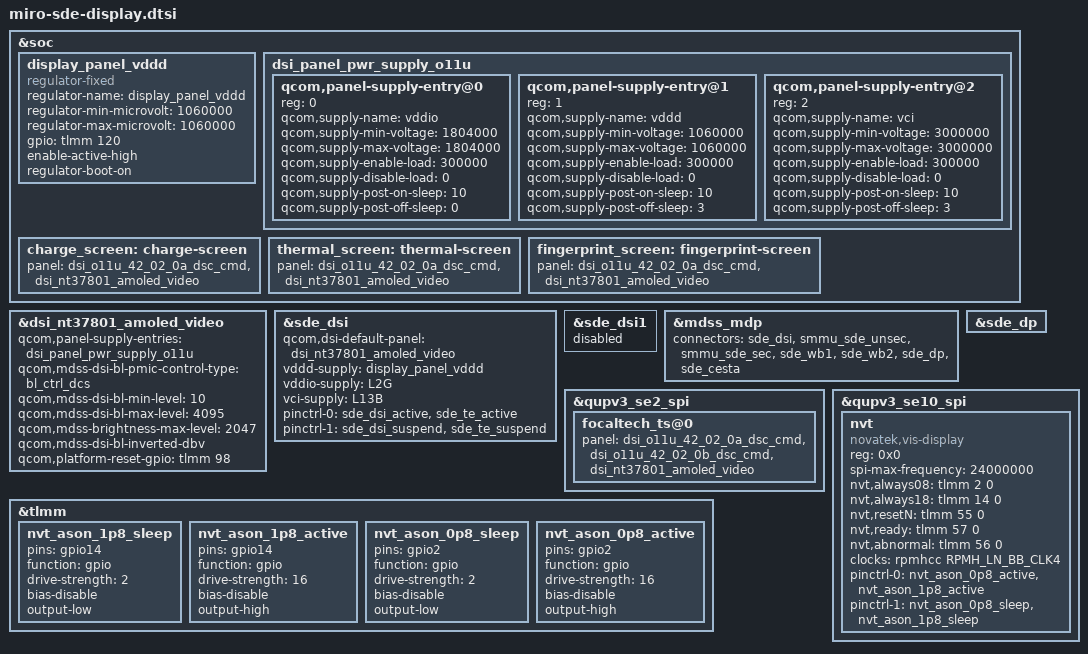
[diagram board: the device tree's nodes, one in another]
#include "sun-sde-display.dtsi"
#include "dsi-panel-o11u-42-02-0a-dsc-cmd.dtsi"
#include "dsi-panel-o11u-42-02-0b-dsc-cmd.dtsi"
#include "dsi-panel-nt37801-dsc-wqhd-plus-video.dtsi"


&soc {
    	display_panel_vddd: display_panel_vddd {
		compatible = "regulator-fixed";
		regulator-name = "display_panel_vddd";
		regulator-min-microvolt = <1060000>;
		regulator-max-microvolt = <1060000>;
		gpio = <&tlmm 120 0>;
		enable-active-high;
		regulator-boot-on;
    };

	dsi_panel_pwr_supply_o11u: dsi_panel_pwr_supply_o11u {
		qcom,panel-supply-entry@0 {
			reg = <0>;
			qcom,supply-name = "vddio";
			qcom,supply-min-voltage = <1804000>;
			qcom,supply-max-voltage = <1804000>;
			qcom,supply-enable-load = <300000>;
			qcom,supply-disable-load = <0>;
			qcom,supply-post-on-sleep = <10>;
			qcom,supply-post-off-sleep = <0>;
		};
		qcom,panel-supply-entry@1 {
			reg = <1>;
			qcom,supply-name = "vddd";
			qcom,supply-min-voltage = <1060000>;
			qcom,supply-max-voltage = <1060000>;
			qcom,supply-enable-load = <300000>;
			qcom,supply-disable-load = <0>;
			qcom,supply-post-on-sleep = <10>;
			qcom,supply-post-off-sleep = <3>;
		};
		qcom,panel-supply-entry@2 {
			reg = <2>;
			qcom,supply-name = "vci";
			qcom,supply-min-voltage = <3000000>;
			qcom,supply-max-voltage = <3000000>;
			qcom,supply-enable-load = <300000>;
			qcom,supply-disable-load = <0>;
			qcom,supply-post-on-sleep = <10>;
			qcom,supply-post-off-sleep = <3>;
		};
	};
};


&dsi_nt37801_amoled_video {
	qcom,panel-supply-entries = <&dsi_panel_pwr_supply_o11u>;
	qcom,mdss-dsi-bl-pmic-control-type = "bl_ctrl_dcs";
	qcom,mdss-dsi-bl-min-level = <10>;
	qcom,mdss-dsi-bl-max-level = <4095>;
	qcom,mdss-brightness-max-level = <2047>;
	qcom,mdss-dsi-bl-inverted-dbv;
	qcom,platform-reset-gpio = <&tlmm 98 0>;
};

&sde_dsi {
	qcom,dsi-default-panel = <&dsi_nt37801_amoled_video>;
	vddd-supply = <&display_panel_vddd>;
	vddio-supply = <&L2G>;
	vci-supply = <&L13B>;
	pinctrl-names = "panel_active", "panel_suspend";
	pinctrl-0 = <&sde_dsi_active &sde_te_active>;
	pinctrl-1 = <&sde_dsi_suspend &sde_te_suspend>;
};

&sde_dsi1 {
	status = "disabled";
};

&mdss_mdp {
	connectors = <&sde_dsi &smmu_sde_unsec &smmu_sde_sec &sde_wb1 &sde_wb2 &sde_dp &sde_cesta>;
};

&sde_dp {
	status = "ok";
};

&qupv3_se2_spi {
	focaltech_ts@0 {
		panel = <&dsi_o11u_42_02_0a_dsc_cmd
			&dsi_o11u_42_02_0b_dsc_cmd
			&dsi_nt37801_amoled_video>;
	};
};

&soc {
	charge_screen: charge-screen {
		panel  = <&dsi_o11u_42_02_0a_dsc_cmd
			&dsi_nt37801_amoled_video>;
	};
};

&soc {
	thermal_screen: thermal-screen {
		panel = <&dsi_o11u_42_02_0a_dsc_cmd
			&dsi_nt37801_amoled_video>;
	};
	fingerprint_screen: fingerprint-screen {
		panel = <&dsi_o11u_42_02_0a_dsc_cmd
			&dsi_nt37801_amoled_video>;
	};
};

/* NVT device tree node and ASIC Start */
&tlmm {
	nvt_ason_1p8_sleep: nvt_ason_1p8_sleep {
		pins = "gpio14";
		function = "gpio";
		drive-strength = <2>;   /* 2 mA */
		bias-disable;
		output-low;
	};

	nvt_ason_1p8_active: nvt_ason_1p8_active {
		pins = "gpio14";
		function = "gpio";
		drive-strength = <16>;   /* 16 mA */
		bias-disable;
		output-high;
	};

	nvt_ason_0p8_sleep: nvt_ason_0p8_sleep {
		pins = "gpio2";
		function = "gpio";
		drive-strength = <2>;   /* 2 mA */
		bias-disable;
		output-low;
	};

	nvt_ason_0p8_active: nvt_ason_0p8_active {
		pins = "gpio2";
		function = "gpio";
		drive-strength = <16>;   /* 16 mA */
		bias-disable;
		output-high;
	};
};


&qupv3_se10_spi {
	status = "ok";

	nvt {
		compatible = "novatek,vis-display";
		reg = <0x0>;
		status = "ok";
		spi-max-frequency = <24000000>;
		nvt,always08 = <&tlmm 2 0>;
		nvt,always18 = <&tlmm 14 0>;
		nvt,resetN = <&tlmm 55 0>;
		nvt,ready = <&tlmm 57 0>;
		nvt,abnormal = <&tlmm 56 0>;
		clocks = <&rpmhcc RPMH_LN_BB_CLK4>;
		clock-names = "mclk";
		pinctrl-names = "default","sleep";
		pinctrl-0 = <&nvt_ason_0p8_active &nvt_ason_1p8_active>;
		pinctrl-1 = <&nvt_ason_0p8_sleep &nvt_ason_1p8_sleep>;
	};
};
/* NVT device tree node and ASIC End */
